# PIC18F26Q43 register map
Vendor: Microchip
Registers are 8-bit, read-write, reset 0x0 unless marked. A register's access mark holds for its fields unless they carry their own. Addresses are absolute, and some are shared; only a register's first bit layout is shown; [hi:lo] are bit positions; {n}, {i} and the like mark numbered series.

## tmr
0x318 TMR0L
0x319 TMR0H reset 0xFF
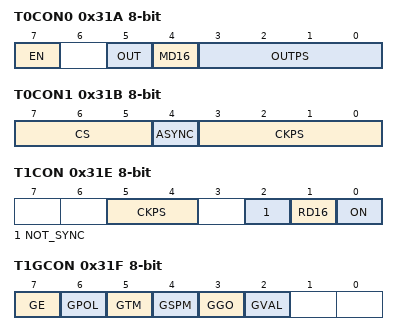
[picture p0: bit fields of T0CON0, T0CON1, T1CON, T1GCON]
0x31A T0CON0
  [7] EN, [5] OUT ro, [4] MD16, [3:0] OUTPS
0x31B T0CON1
  [7:5] CS, [4] ASYNC, [3:0] CKPS
0x31C TMR1L
0x31D TMR1H
0x31E T1CON
  [5:4] CKPS, [2] NOT_SYNC, [1] RD16, [0] ON
0x31F T1GCON reset not defined — (power-on value 00000x--)
  [7] GE, [6] GPOL, [5] GTM, [4] GSPM, [3] GGO, [2] GVAL ro
0x320 T1GATE
  [5:0] GSS
0x321 T1CLK
  [4:0] CS
0x322 T2TMR — 8-bit period timer
  [7:0] TMR2
0x323 T2PR reset 0xFF
  [7:0] PR2
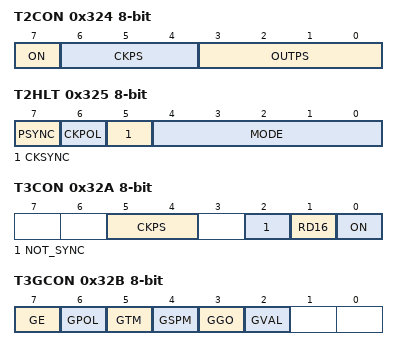
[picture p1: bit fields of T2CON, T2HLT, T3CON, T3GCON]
0x324 T2CON
  [7] ON, [6:4] CKPS, [3:0] OUTPS
0x325 T2HLT
  [7] PSYNC, [6] CKPOL, [5] CKSYNC, [4:0] MODE
0x326 T2CLKCON
  [5:0] CS
0x327 T2RST
  [6:0] RSEL
0x328 TMR3L
0x329 TMR3H
0x32A T3CON
  [5:4] CKPS, [2] NOT_SYNC, [1] RD16, [0] ON
0x32B T3GCON reset not defined — (power-on value 00000x--)
  [7] GE, [6] GPOL, [5] GTM, [4] GSPM, [3] GGO, [2] GVAL ro
0x32C T3GATE
  [5:0] GSS
0x32D T3CLK
  [4:0] CS
0x32E T4TMR — 8-bit period timer
  [7:0] TMR4
0x32F T4PR reset 0xFF
  [7:0] PR4
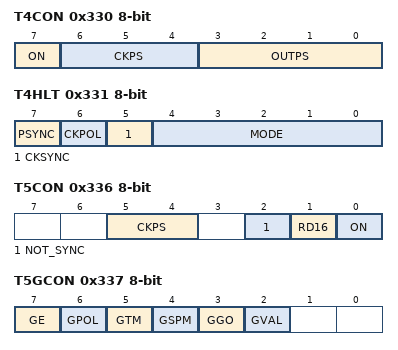
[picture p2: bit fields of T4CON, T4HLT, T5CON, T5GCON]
0x330 T4CON
  [7] ON, [6:4] CKPS, [3:0] OUTPS
0x331 T4HLT
  [7] PSYNC, [6] CKPOL, [5] CKSYNC, [4:0] MODE
0x332 T4CLKCON
  [5:0] CS
0x333 T4RST
  [6:0] RSEL
0x334 TMR5L
0x335 TMR5H
0x336 T5CON
  [5:4] CKPS, [2] NOT_SYNC, [1] RD16, [0] ON
0x337 T5GCON reset not defined — (power-on value 00000x--)
  [7] GE, [6] GPOL, [5] GTM, [4] GSPM, [3] GGO, [2] GVAL ro
0x338 T5GATE
  [5:0] GSS
0x339 T5CLK
  [4:0] CS
0x33A T6TMR — 8-bit period timer
  [7:0] TMR6
0x33B T6PR reset 0xFF
  [7:0] PR6
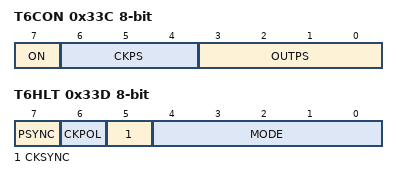
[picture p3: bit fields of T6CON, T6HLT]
0x33C T6CON
  [7] ON, [6:4] CKPS, [3:0] OUTPS
0x33D T6HLT
  [7] PSYNC, [6] CKPOL, [5] CKSYNC, [4:0] MODE
0x33E T6CLKCON
  [5:0] CS
0x33F T6RST
  [6:0] RSEL

## ccp
{0x33C+4i} CCPR{i}L reset not defined (i=1..3) — (power-on value xxxxxxxx)
  [7:0] RL
{0x33D+4i} CCPR{i}H reset not defined (i=1..3) — (power-on value xxxxxxxx)
  [7:0] RH
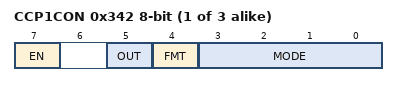
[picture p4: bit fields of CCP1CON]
{0x33E+4i} CCP{i}CON (i=1..3)
  [7] EN, [5] OUT ro, [4] FMT, [3:0] MODE
{0x33F+4i} CCP{i}CAP (i=1..3)
  [3:0] CTS

## math_progcrc
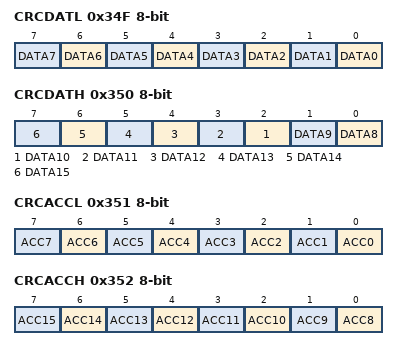
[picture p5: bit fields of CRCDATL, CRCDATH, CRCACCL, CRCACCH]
0x34F CRCDATL reset not defined — (power-on value xxxxxxxx)
  [n] DATA{n} (n=0..7)
0x350 CRCDATH reset not defined — (power-on value xxxxxxxx)
  [n-8] DATA{n} (n=8..15)
0x351 CRCACCL
  [n] ACC{n} (n=0..7)
0x352 CRCACCH
  [n-8] ACC{n} (n=8..15)
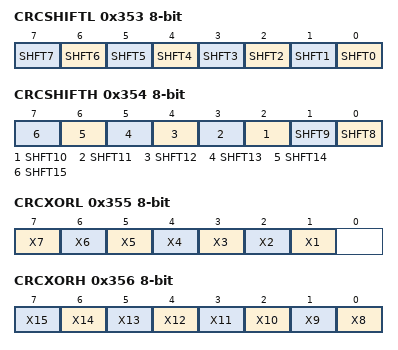
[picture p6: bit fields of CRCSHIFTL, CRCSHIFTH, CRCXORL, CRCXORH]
0x353 CRCSHIFTL ro
  [n] SHFT{n} (n=0..7)
0x354 CRCSHIFTH ro
  [n-8] SHFT{n} (n=8..15)
0x355 CRCXORL reset not defined — (power-on value xxxxxxx1)
  [n] X{n} (n=1..7)
0x356 CRCXORH reset not defined — (power-on value xxxxxxxx)
  [n-8] X{n} (n=8..15)
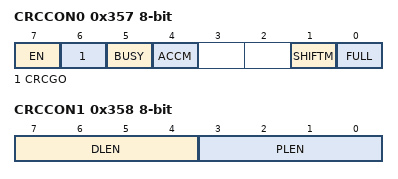
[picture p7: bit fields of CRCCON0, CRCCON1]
0x357 CRCCON0
  [7] EN, [6] CRCGO, [5] BUSY ro, [4] ACCM, [1] SHIFTM, [0] FULL ro
0x358 CRCCON1
  [7:4] DLEN, [3:0] PLEN

## nvm_scan
0x35A SCANLADRL
  [7:0] LADR
0x35B SCANLADRH
  [7:0] LADR
0x35C SCANLADRU
  [5:0] LADR
0x35D SCANHADRL reset 0xFF
  [7:0] HADR
0x35E SCANHADRH reset 0xFF
  [7:0] HADR
0x35F SCANHADRU reset 0x3F
  [5:0] HADR
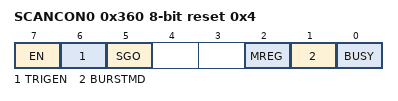
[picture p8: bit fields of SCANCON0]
0x360 SCANCON0 reset 0x4
  [7] EN, [6] TRIGEN, [5] SGO, [2] MREG, [1] BURSTMD, [0] BUSY
0x361 SCANTRIG
  [4:0] TSEL

## wg_ecwg
{0x3B3+9i} CWG{i}CLK (i=1..3)
  [0] CS
{0x3B4+9i} CWG{i}ISM (i=1..3)
  [4:0] ISM
{0x3B5+9i} CWG{i}DBR (i=1..3)
  [5:0] DBR
{0x3B6+9i} CWG{i}DBF (i=1..3)
  [5:0] DBF
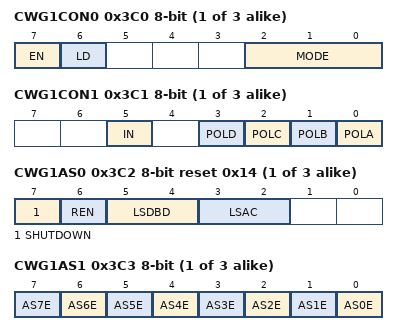
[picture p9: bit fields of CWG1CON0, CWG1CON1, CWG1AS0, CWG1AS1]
{0x3B7+9i} CWG{i}CON0 (i=1..3)
  [7] EN, [6] LD, [2:0] MODE
{0x3B8+9i} CWG{i}CON1 reset not defined (i=1..3) — (power-on value --x-0000)
  [5] IN ro, [3] POLD, [2] POLC, [1] POLB, [0] POLA
{0x3B9+9i} CWG{i}AS0 reset 0x14 (i=1..3)
  [7] SHUTDOWN, [6] REN, [5:4] LSDBD, [3:2] LSAC
{0x3BA+9i} CWG{i}AS1 (i=1..3)
  [n] AS{n}E (n=0..7)
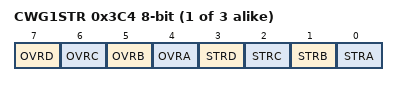
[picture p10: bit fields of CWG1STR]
{0x3BB+9i} CWG{i}STR (i=1..3)
  [7] OVRD, [6] OVRC, [5] OVRB, [4] OVRA, [3] STRD, [2] STRC, [1] STRB, [0] STRA

## amp_fvr_ts_ctrl
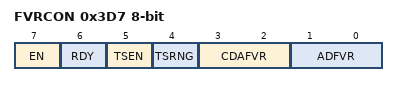
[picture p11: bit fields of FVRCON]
0x3D7 FVRCON reset not defined — (power-on value xx000000)
  [7] EN — Zero-Cross Detect Software Enable bit
  [6] RDY ro
  [5] TSEN — Zero-Cross Detect Data Output
  [4] TSRNG — Zero-Cross Detect Polarity bit
  [3:2] CDAFVR
  [1:0] ADFVR — Zero-Cross Detect Positive-going Edge Interrupt Enable
